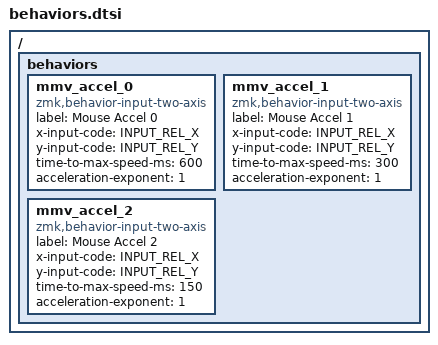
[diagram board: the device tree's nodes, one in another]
/ {
    behaviors {
        mmv_accel_0: mmv_accel_0 {
            compatible = "zmk,behavior-input-two-axis";
            label = "Mouse Accel 0";
            x-input-code = <INPUT_REL_X>;
            y-input-code = <INPUT_REL_Y>;
            time-to-max-speed-ms = <600>;
            acceleration-exponent = <1>;
        };

        mmv_accel_1: mmv_accel_1 {
            compatible = "zmk,behavior-input-two-axis";
            label = "Mouse Accel 1";
            x-input-code = <INPUT_REL_X>;
            y-input-code = <INPUT_REL_Y>;
            time-to-max-speed-ms = <300>;
            acceleration-exponent = <1>;
        };

        mmv_accel_2: mmv_accel_2 {
            compatible = "zmk,behavior-input-two-axis";
            label = "Mouse Accel 2";
            x-input-code = <INPUT_REL_X>;
            y-input-code = <INPUT_REL_Y>;
            time-to-max-speed-ms = <150>;
            acceleration-exponent = <1>;
        };
    };
};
